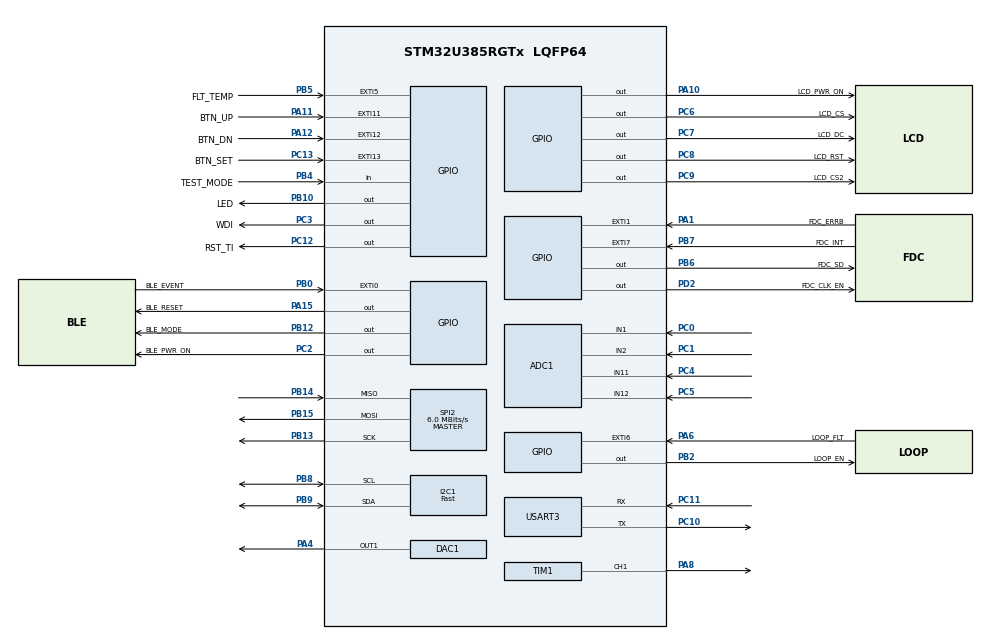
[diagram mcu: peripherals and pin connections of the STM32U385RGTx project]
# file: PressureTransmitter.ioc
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ADC1.Channel-0\#ChannelRegularConversion=ADC_CHANNEL_1
ADC1.Channel-1\#ChannelRegularConversion=ADC_CHANNEL_2
ADC1.Channel-2\#ChannelRegularConversion=ADC_CHANNEL_11
ADC1.Channel-3\#ChannelRegularConversion=ADC_CHANNEL_12
ADC1.ContinuousConvMode=DISABLE
ADC1.ConversionDataManagement=ADC_CONVERSIONDATA_DMA_ONESHOT
ADC1.EOCSelection=ADC_EOC_SEQ_CONV
ADC1.MonitoredBy-0\#ChannelRegularConversion=__NULL
ADC1.MonitoredBy-1\#ChannelRegularConversion=__NULL
ADC1.MonitoredBy-2\#ChannelRegularConversion=__NULL
ADC1.MonitoredBy-3\#ChannelRegularConversion=__NULL
ADC1.NbrOfConversion=4
ADC1.NbrOfConversionFlag=1
ADC1.OffsetNumber-0\#ChannelRegularConversion=ADC_OFFSET_NONE
ADC1.OffsetNumber-1\#ChannelRegularConversion=ADC_OFFSET_NONE
ADC1.OffsetNumber-2\#ChannelRegularConversion=ADC_OFFSET_NONE
ADC1.OffsetNumber-3\#ChannelRegularConversion=ADC_OFFSET_NONE
ADC1.Rank-0\#ChannelRegularConversion=1
ADC1.Rank-1\#ChannelRegularConversion=2
ADC1.Rank-2\#ChannelRegularConversion=3
ADC1.Rank-3\#ChannelRegularConversion=4
ADC1.SamplingTime-0\#ChannelRegularConversion=ADC_SAMPLETIME_1CYCLE_5
ADC1.SamplingTime-1\#ChannelRegularConversion=ADC_SAMPLETIME_1CYCLE_5
ADC1.SamplingTime-2\#ChannelRegularConversion=ADC_SAMPLETIME_1CYCLE_5
ADC1.SamplingTime-3\#ChannelRegularConversion=ADC_SAMPLETIME_1CYCLE_5
ADC1.master=1
CORTEX_M33_NS.userName=CORTEX_M33
DAC1.DAC_Channel-DAC_OUT1=DAC_CHANNEL_1
DAC1.DAC_OutputBuffer_OUT1-DAC_OUT1=DAC_OUTPUTBUFFER_ENABLE
GPDMA1.CIRCULARMODE_GPDMACH0=DISABLE
GPDMA1.DESTDATAWIDTH_GPDMACH0=DMA_DEST_DATAWIDTH_HALFWORD
GPDMA1.DESTINC_GPDMACH0=DMA_DINC_INCREMENTED
GPDMA1.IPHANDLE_GPDMACH0-SIMPLEREQUEST_GPDMACH0=__NULL
GPDMA1.REQUEST_GPDMACH0=GPDMA1_REQUEST_ADC1
GPDMA1.SRCDATAWIDTH_GPDMACH0=DMA_SRC_DATAWIDTH_HALFWORD
I2C1.I2C_Speed_Mode=I2C_Fast
I2C1.Timing=0x2010091A
IWDG.Prescaler=IWDG_PRESCALER_64
IWDG.Window=4095
Mcu.Family=STM32U3
Mcu.Name=STM32U385RGTx
Mcu.Package=LQFP64
NVIC.ADC1_IRQn=true\:0\:0\:false\:false\:true\:true\:true\:true
NVIC.EXTI0_IRQn=true\:0\:0\:false\:false\:true\:true\:true\:true
NVIC.EXTI11_IRQn=true\:0\:0\:false\:false\:true\:true\:true\:true
NVIC.EXTI12_IRQn=true\:0\:0\:false\:false\:true\:true\:true\:true
NVIC.EXTI13_IRQn=true\:0\:0\:false\:false\:true\:true\:true\:true
NVIC.EXTI1_IRQn=true\:0\:0\:false\:false\:true\:true\:true\:true
NVIC.EXTI5_IRQn=true\:0\:0\:false\:false\:true\:true\:true\:true
NVIC.EXTI6_IRQn=true\:0\:0\:false\:false\:true\:true\:true\:true
NVIC.EXTI7_IRQn=true\:0\:0\:false\:false\:true\:true\:true\:true
NVIC.GPDMA1_Channel0_IRQn=true\:0\:0\:false\:false\:true\:false\:true\:true
NVIC.IWDG_IRQn=true\:0\:0\:false\:false\:true\:true\:true\:true
NVIC.PriorityGroup=NVIC_PRIORITYGROUP_4
NVIC.TIM6_IRQn=true\:15\:0\:false\:false\:true\:false\:true\:true
NVIC.TimeBase=TIM6_IRQn
NVIC.TimeBaseIP=TIM6
PA1.GPIO_Label=FDC_ERRB
PA1.GPIO_ModeDefaultEXTI=GPIO_MODE_IT_FALLING
PA1.GPIO_PuPd=GPIO_PULLUP
PA1.Signal=GPXTI1
PA10.GPIO_Label=LCD_PWR_ON
PA10.Signal=GPIO_Output
PA11.GPIO_Label=BTN_UP
PA11.GPIO_ModeDefaultEXTI=GPIO_MODE_IT_FALLING
PA11.GPIO_PuPd=GPIO_PULLUP
PA11.Signal=GPXTI11
PA12.GPIO_Label=BTN_DN
PA12.GPIO_ModeDefaultEXTI=GPIO_MODE_IT_FALLING
PA12.GPIO_PuPd=GPIO_PULLUP
PA12.Signal=GPXTI12
PA13\ (JTMS/SWDIO).Mode=Trace_Asynchronous_SW
PA13\ (JTMS/SWDIO).Signal=DEBUG_JTMS-SWDIO
PA14\ (JTCK/SWCLK).Mode=Trace_Asynchronous_SW
PA14\ (JTCK/SWCLK).Signal=DEBUG_JTCK-SWCLK
PA15\ (JTDI).GPIO_Label=BLE_RESET
PA15\ (JTDI).GPIO_ModeDefaultOutputPP=GPIO_MODE_OUTPUT_OD
PA15\ (JTDI).GPIO_PuPd=GPIO_NOPULL
PA15\ (JTDI).PinState=GPIO_PIN_SET
PA15\ (JTDI).Signal=GPIO_Output
PA4.Signal=COMP_DAC11_group
PA6.GPIO_Label=LOOP_FLT
PA6.GPIO_ModeDefaultEXTI=GPIO_MODE_IT_FALLING
PA6.GPIO_PuPd=GPIO_PULLUP
PA6.Signal=GPXTI6
PA8.Signal=S_TIM1_CH1
PB0.GPIO_Label=BLE_EVENT
PB0.GPIO_ModeDefaultEXTI=GPIO_MODE_IT_FALLING
PB0.Signal=GPXTI0
PB10.GPIO_Label=LED
PB10.Signal=GPIO_Output
PB12.GPIO_Label=BLE_MODE
PB12.Signal=GPIO_Output
PB13.Mode=Full_Duplex_Master
PB13.Signal=SPI2_SCK
PB14.Mode=Full_Duplex_Master
PB14.Signal=SPI2_MISO
PB15.Mode=Full_Duplex_Master
PB15.Signal=SPI2_MOSI
PB2.GPIO_Label=LOOP_EN
PB2.Signal=GPIO_Output
PB3\ (JTDO/TRACESWO).Mode=Trace_Asynchronous_SW
PB3\ (JTDO/TRACESWO).Signal=DEBUG_JTDO-SWO
PB4\ (NJTRST).GPIO_Label=TEST_MODE
PB4\ (NJTRST).GPIO_PuPd=GPIO_PULLDOWN
PB4\ (NJTRST).Signal=GPIO_Input
PB5.GPIO_Label=FLT_TEMP
PB5.GPIO_ModeDefaultEXTI=GPIO_MODE_IT_FALLING
PB5.Signal=GPXTI5
PB6.GPIO_Label=FDC_SD
PB6.Signal=GPIO_Output
PB7.GPIO_Label=FDC_INT
PB7.GPIO_ModeDefaultEXTI=GPIO_MODE_IT_FALLING
PB7.Signal=GPXTI7
PB8.Mode=I2C
PB8.Signal=I2C1_SCL
PB9.Mode=I2C
PB9.Signal=I2C1_SDA
PC0.Mode=IN1-Single-Ended
PC0.Signal=ADC1_IN1
PC1.Mode=IN2-Single-Ended
PC1.Signal=ADC1_IN2
PC10.Mode=Asynchronous
PC10.Signal=USART3_TX
PC11.Mode=Asynchronous
PC11.Signal=USART3_RX
PC12.GPIO_Label=RST_TI
PC12.PinState=GPIO_PIN_SET
PC12.Signal=GPIO_Output
PC13.GPIO_Label=BTN_SET
PC13.GPIO_ModeDefaultEXTI=GPIO_MODE_IT_FALLING
PC13.GPIO_PuPd=GPIO_PULLUP
PC13.Signal=GPXTI13
PC14-OSC32_IN\ (PC14).Mode=LSE-External-Oscillator
PC14-OSC32_IN\ (PC14).Signal=RCC_OSC32_IN
PC15-OSC32_OUT\ (PC15).Mode=LSE-External-Oscillator
PC15-OSC32_OUT\ (PC15).Signal=RCC_OSC32_OUT
PC2.GPIO_Label=BLE_PWR_ON
PC2.Signal=GPIO_Output
PC3.GPIO_Label=WDI
PC3.Signal=GPIO_Output
PC4.Mode=IN11-Single-Ended
PC4.Signal=ADC1_IN11
PC5.Mode=IN12-Single-Ended
PC5.Signal=ADC1_IN12
PC6.GPIO_Label=LCD_CS
PC6.GPIO_Speed=GPIO_SPEED_FREQ_HIGH
PC6.PinState=GPIO_PIN_SET
PC6.Signal=GPIO_Output
PC7.GPIO_Label=LCD_DC
PC7.Signal=GPIO_Output
PC8.GPIO_Label=LCD_RST
PC8.Signal=GPIO_Output
PC9.GPIO_Label=LCD_CS2
PC9.PinState=GPIO_PIN_SET
PC9.Signal=GPIO_Output
PD2.GPIO_Label=FDC_CLK_EN
PD2.PinState=GPIO_PIN_SET
PD2.Signal=GPIO_Output
PH0-OSC_IN\ (PH0).Mode=HSE-External-Oscillator
PH0-OSC_IN\ (PH0).Signal=RCC_OSC_IN
PH1-OSC_OUT\ (PH1).Mode=HSE-External-Oscillator
PH1-OSC_OUT\ (PH1).Signal=RCC_OSC_OUT
ProjectManager.HeapSize=0x200
ProjectManager.StackSize=0x800
ProjectManager.TargetToolchain=CMake
RCC.ADCFreq_Value=48000000
RCC.AHBCLKDivider=RCC_SYSCLK_DIV2
RCC.AHBFreq_Value=48000000
RCC.APB1Freq_Value=48000000
RCC.APB1TimFreq_Value=48000000
RCC.APB2Freq_Value=48000000
RCC.APB2TimFreq_Value=48000000
RCC.APB3Freq_Value=48000000
RCC.CortexFreq_Value=6000000
RCC.HCLKFreq_Value=48000000
RCC.HSE_VALUE=24000000
RCC.HSI48_VALUE=48000000
RCC.HSI_VALUE=16000000
RCC.LSIDIV_VALUE=32000
RCC.MSISDIV=RCC_MSI_DIV1
RCC.SYSCLKFreq_VALUE=96000000
RCC.USBFreq_Value=96000000
SH.COMP_DAC11_group.0=DAC1_OUT1,DAC_OUT1
SH.S_TIM1_CH1.0=TIM1_CH1,PWM Generation1 CH1
SPI2.BaudRatePrescaler=SPI_BAUDRATEPRESCALER_8
SPI2.CalculateBaudRate=6.0 MBits/s
SPI2.DataSize=SPI_DATASIZE_8BIT
SPI2.Direction=SPI_DIRECTION_2LINES
SPI2.Mode=SPI_MODE_MASTER
SPI2.NSSPMode=SPI_NSS_PULSE_DISABLE
SPI2.VirtualType=VM_MASTER
TIM1.AutoReloadPreload=TIM_AUTORELOAD_PRELOAD_ENABLE
TIM1.Channel-PWM\ Generation1\ CH1=TIM_CHANNEL_1
TIM1.PeriodNoDither=99
TIM1.Prescaler=47
TIM1.PulseNoDither_1=60
USART3.VirtualMode-Asynchronous=VM_ASYNC
VP_GPDMA1_VS_GPDMACH0.Mode=SIMPLEREQUEST_GPDMACH0
VP_IWDG_VS_IWDG.Mode=IWDG_Activate
VP_MEMORYMAP_VS_MEMORYMAP.Mode=CurAppReg
VP_PWR_VS_DBSignals.Mode=DisableDeadBatterySignals
VP_PWR_VS_LPOM.Mode=PowerOptimisation
VP_PWR_VS_SECSignals.Mode=Security/Privilege
VP_SYS_VS_tim6.Mode=TIM6
VP_TIM1_VS_ClockSourceINT.Mode=Internal
board=custom

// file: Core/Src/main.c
/* USER CODE BEGIN Header */
/**
  ******************************************************************************
  * @file           : main.c
  * @brief          : Main program body
  ******************************************************************************
  * @attention
  *
  * Copyright (c) 2026 STMicroelectronics.
  * All rights reserved.
  *
  * This software is licensed under terms that can be found in the LICENSE file
  * in the root directory of this software component.
  * If no LICENSE file comes with this software, it is provided AS-IS.
  *
  ******************************************************************************
  */
/* USER CODE END Header */
#include "main.h"
#include "adc.h"
#include "dac.h"
#include "gpdma.h"
#include "i2c.h"
#include "iwdg.h"
#include "spi.h"
#include "tim.h"
#include "usart.h"
#include "gpio.h"

/* USER CODE BEGIN Includes */
#include "pressure_app.h"
#include "buttons.h"
#include "xtr111_loop.h"
#include "tmp108.h"
/* USER CODE END Includes */

void SystemClock_Config(void);

int main(void)
{

  /* MCU Configuration--------------------------------------------------------*/

  /* Reset of all peripherals, Initializes the Flash interface and the Systick. */
  HAL_Init();

  /* Configure the system clock */
  SystemClock_Config();

  /* Initialize all configured peripherals */
  MX_GPIO_Init();
  MX_GPDMA1_Init();
  MX_ADC1_Init();
  MX_DAC1_Init();
  MX_I2C1_Init();
  MX_IWDG_Init();
  MX_SPI2_Init();
  MX_TIM1_Init();
  MX_USART3_UART_Init();
  /* USER CODE BEGIN 2 */
  pressure_app_init();
  /* USER CODE END 2 */

  /* Infinite loop */
  /* USER CODE BEGIN WHILE */
  while (1)
  {
    pressure_app_loop();
    /* USER CODE END WHILE */

  }
}

void SystemClock_Config(void)
{
  RCC_OscInitTypeDef RCC_OscInitStruct = {0};
  RCC_ClkInitTypeDef RCC_ClkInitStruct = {0};

  /** Enable Epod Booster
  */
  if (HAL_RCCEx_EpodBoosterClkConfig(RCC_EPODBOOSTER_SOURCE_MSIS, RCC_EPODBOOSTER_DIV1) != HAL_OK)
  {
    Error_Handler();
  }
  if (HAL_PWREx_EnableEpodBooster() != HAL_OK)
  {
    Error_Handler();
  }

  /** Configure the main internal regulator output voltage
  */
  if (HAL_PWREx_ControlVoltageScaling(PWR_REGULATOR_VOLTAGE_SCALE1) != HAL_OK)
  {
    Error_Handler();
  }

  /** Set Flash latency before increasing MSIS
  */
  __HAL_FLASH_SET_LATENCY(FLASH_LATENCY_1);

  /** Initializes the CPU, AHB and APB buses clocks
  */
  RCC_OscInitStruct.OscillatorType = RCC_OSCILLATORTYPE_LSI|RCC_OSCILLATORTYPE_MSIS;
  RCC_OscInitStruct.LSIState = RCC_LSI_ON;
  RCC_OscInitStruct.LSIDiv = RCC_LSI_DIV1;
  RCC_OscInitStruct.MSISState = RCC_MSI_ON;
  RCC_OscInitStruct.MSISSource = RCC_MSI_RC0;
  RCC_OscInitStruct.MSISDiv = RCC_MSI_DIV1;
  if (HAL_RCC_OscConfig(&RCC_OscInitStruct) != HAL_OK)
  {
    Error_Handler();
  }

  /** Initializes the CPU, AHB and APB buses clocks
  */
  RCC_ClkInitStruct.ClockType = RCC_CLOCKTYPE_HCLK|RCC_CLOCKTYPE_SYSCLK
                              |RCC_CLOCKTYPE_PCLK1|RCC_CLOCKTYPE_PCLK2
                              |RCC_CLOCKTYPE_PCLK3;
  RCC_ClkInitStruct.SYSCLKSource = RCC_SYSCLKSOURCE_MSIS;
  RCC_ClkInitStruct.AHBCLKDivider = RCC_SYSCLK_DIV2;
  RCC_ClkInitStruct.APB1CLKDivider = RCC_HCLK_DIV1;
  RCC_ClkInitStruct.APB2CLKDivider = RCC_HCLK_DIV1;
  RCC_ClkInitStruct.APB3CLKDivider = RCC_HCLK_DIV1;

  if (HAL_RCC_ClockConfig(&RCC_ClkInitStruct, FLASH_LATENCY_1) != HAL_OK)
  {
    Error_Handler();
  }
}

/* USER CODE BEGIN 4 */
/**
 * EXTI Falling-edge callback (HAL otomatik çağırır).
 * 3 Hall butonu (UP/DN/SET) + XTR111 fault input için pinleri yönlendir.
 */
void HAL_GPIO_EXTI_Falling_Callback(uint16_t pin)
{
    if (pin == BTN_UP_Pin)        buttons_on_edge(BTN_ID_UP);
    else if (pin == BTN_DN_Pin)   buttons_on_edge(BTN_ID_DN);
    else if (pin == BTN_SET_Pin)  buttons_on_edge(BTN_ID_SET);
    else if (pin == LOOP_FLT_Pin) loop_on_flt_edge();   /* enable glitch maskeli */
    else if (pin == FLT_TEMP_Pin) tmp108_on_alert_edge();   /* ortam >60 C */
    /* Diğer EXTI'ler (FDC_INT, FDC_ERRB, BLE_EVENT) şimdilik polling */
}
/* USER CODE END 4 */

void HAL_TIM_PeriodElapsedCallback(TIM_HandleTypeDef *htim)
{
  if (htim->Instance == TIM6)
  {
    HAL_IncTick();
  }
}

void Error_Handler(void)
{
  __disable_irq();
  while (1)
  {
  }
}
